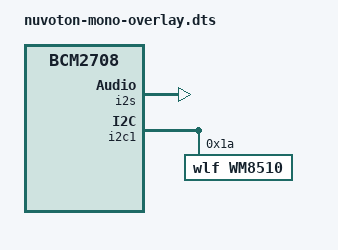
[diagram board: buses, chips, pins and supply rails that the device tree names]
// Definitions for Nuvoton Mono
/dts-v1/;
/plugin/;

/ {
	compatible = "brcm,bcm2708";

	fragment@0 {
		target = <&sound>;
		__overlay__ {
			compatible = "nuvoton,nuvoton-mono";
			i2s-controller = <&i2s>;
			status = "okay";
		};
	};

	fragment@1 {
		target = <&i2s>;
		__overlay__ {
			status = "okay";
		};
	};

	fragment@2 {
		target = <&i2c1>;
		__overlay__ {
			#address-cells = <1>;
			#size-cells = <0>;
			status = "okay";

			wm8510@3b {
				#sound-dai-cells = <0>;
				compatible = "wlf,wm8510";
				reg = <0x1a>;
				status = "okay";
			};
		};
	};
};
